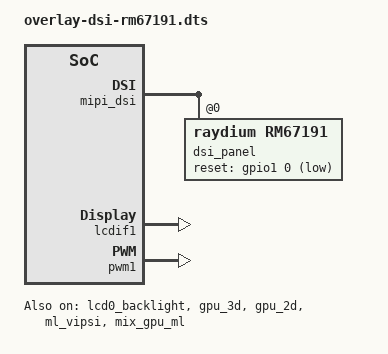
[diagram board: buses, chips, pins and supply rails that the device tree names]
/*
 * Copyright (C) 2022 Avnet Embedded GmbH
 *
 * This program is free software; you can redistribute it and/or
 * modify it under the terms of the GNU General Public License as
 * published by the Free Software Foundation version 2.
 *
 * This program is distributed "as is" WITHOUT ANY WARRANTY of any
 * kind, whether express or implied; without even the implied warranty
 * of MERCHANTABILITY or FITNESS FOR A PARTICULAR PURPOSE.  See the
 * GNU General Public License for more details.
 */


/dts-v1/;
/plugin/;

#include <dt-bindings/gpio/gpio.h>

/ {
	fragment@4200 {
		target = <&mipi_dsi>;
		__overlay__ {
			#address-cells = <1>;
			#size-cells = <0>;
			status = "okay";
			dsi_panel: panel@0 {
				reg = <0>;
				pinctrl-names = "default";
				pinctrl-0 = <&pinctrl_lcd0_panel>;
				compatible = "raydium,rm67191";

				reset-gpios = <&gpio1 0 GPIO_ACTIVE_LOW>;
				dsi-lanes = <4>;
				video-mode = <2>;	/* 0: burst mode
							 * 1: non-burst mode with sync event
							 * 2: non-burst mode with sync pulse
							 */
				panel-width-mm = <68>;
				panel-height-mm = <121>;
				status = "okay";
			};
		};
	};

	fragment@4201 {
		target = <&lcdif1>;
		__overlay__ {
			status = "okay";
		};
	};

	fragment@4202 {
		target = <&pwm1>;
		__overlay__ {
			status = "okay";
		};
	};

	fragment@4203 {
		target = <&lcd0_backlight>;
		__overlay__ {
			status = "okay";
		};
	};

	fragment@4204 {
		target = <&gpu_3d>;
		__overlay__ {
			status = "okay";
		};
	};

	fragment@4205 {
		target = <&gpu_2d>;
		__overlay__ {
			status = "okay";
		};
	};

	fragment@4206 {
		target = <&ml_vipsi>;
		__overlay__ {
			status = "okay";
		};
	};

	fragment@4207 {
		target = <&mix_gpu_ml>;
		__overlay__ {
			status = "okay";
		};
	};
};
